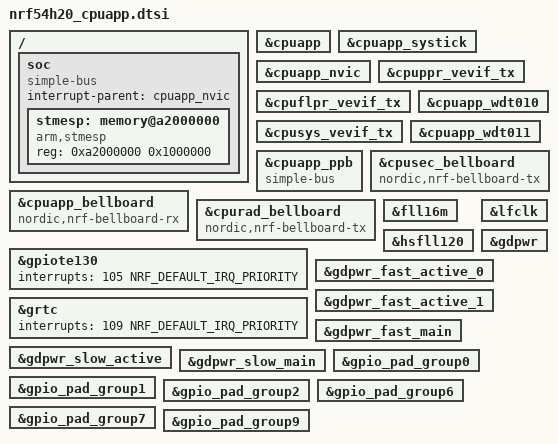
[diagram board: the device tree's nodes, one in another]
/*
 * Copyright (c) 2024 Nordic Semiconductor ASA
 *
 * SPDX-License-Identifier: Apache-2.0
 */

#include <nordic/nrf54h20.dtsi>

cpu: &cpuapp {};
systick: &cpuapp_systick {};
nvic: &cpuapp_nvic {};
cpuppr_vevif: &cpuppr_vevif_tx {};
cpuflpr_vevif: &cpuflpr_vevif_tx {};
cpusys_vevif: &cpusys_vevif_tx {};
wdt010: &cpuapp_wdt010 {};
wdt011: &cpuapp_wdt011 {};

/delete-node/ &cpuppr;
/delete-node/ &cpuflpr;
/delete-node/ &cpurad;
/delete-node/ &cpurad_peripherals;
/delete-node/ &cpurad_ppb;
/delete-node/ &cpurad_ram0;

/ {
	soc {
		compatible = "simple-bus";
		interrupt-parent = <&cpuapp_nvic>;
		ranges;

		stmesp: memory@a2000000 {
			compatible = "arm,stmesp";
			reg = <0xa2000000 0x1000000>;
		};
	};
};

&cpuapp_ppb {
	compatible = "simple-bus";
	ranges;
};

&cpusec_bellboard {
	compatible = "nordic,nrf-bellboard-tx";
};

&cpuapp_bellboard {
	compatible = "nordic,nrf-bellboard-rx";
};

&cpurad_bellboard {
	compatible = "nordic,nrf-bellboard-tx";
};

&gpiote130 {
	interrupts = <105 NRF_DEFAULT_IRQ_PRIORITY>;
};

&grtc {
	interrupts = <109 NRF_DEFAULT_IRQ_PRIORITY>;
};

&fll16m  {
	status = "okay";
};

&hsfll120  {
	status = "okay";
};

&lfclk  {
	status = "okay";
};

&gdpwr {
	status = "okay";
};

&gdpwr_fast_active_0 {
	status = "okay";
};

&gdpwr_fast_active_1 {
	status = "okay";
};

&gdpwr_fast_main {
	status = "okay";
};

&gdpwr_slow_active {
	status = "okay";
};

&gdpwr_slow_main {
	status = "okay";
};

&gpio_pad_group0 {
	status = "okay";
};

&gpio_pad_group1 {
	status = "okay";
};

&gpio_pad_group2 {
	status = "okay";
};

&gpio_pad_group6 {
	status = "okay";
};

&gpio_pad_group7 {
	status = "okay";
};

&gpio_pad_group9 {
	status = "okay";
};
